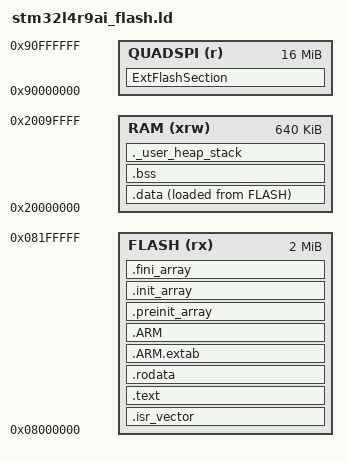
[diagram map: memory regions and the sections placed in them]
/*
******************************************************************************
File:     stm32l4r9ai_flash.ld
Info:     Generated by Atollic TrueSTUDIO(R) 9.2.0   2018-12-17

Abstract: Linker script for STM32L4R9AI device
          Set heap size, stack size, stack location, memory areas and
          sections according to application requirements.

The MIT License (MIT)
Copyright (c) 2018 STMicroelectronics

Permission is hereby granted, free of charge, to any person obtaining a copy
of this software and associated documentation files (the "Software"), to deal
in the Software without restriction, including without limitation the rights
to use, copy, modify, merge, publish, distribute, sublicense, and/or sell
copies of the Software, and to permit persons to whom the Software is
furnished to do so, subject to the following conditions:

The above copyright notice and this permission notice shall be included in all
copies or substantial portions of the Software.

THE SOFTWARE IS PROVIDED "AS IS", WITHOUT WARRANTY OF ANY KIND, EXPRESS OR
IMPLIED, INCLUDING BUT NOT LIMITED TO THE WARRANTIES OF MERCHANTABILITY,
FITNESS FOR A PARTICULAR PURPOSE AND NONINFRINGEMENT. IN NO EVENT SHALL THE
AUTHORS OR COPYRIGHT HOLDERS BE LIABLE FOR ANY CLAIM, DAMAGES OR OTHER
LIABILITY, WHETHER IN AN ACTION OF CONTRACT, TORT OR OTHERWISE, ARISING FROM,
OUT OF OR IN CONNECTION WITH THE SOFTWARE OR THE USE OR OTHER DEALINGS IN THE
SOFTWARE.

******************************************************************************
*/

/* Entry Point */
ENTRY(Reset_Handler)

/* Highest address of the user mode stack */
_estack = 0x200A0000;    /* end of 640K RAM */

/* Generate a link error if heap and stack don't fit into RAM */
_Min_Heap_Size = 0;      /* required amount of heap  */
_Min_Stack_Size = 0x400; /* required amount of stack */

/* Specify the memory areas: 1 SRAM bank */
MEMORY
{
	RAM (xrw)      : ORIGIN = 0x20000000, LENGTH = 640K
	FLASH (rx)     : ORIGIN = 0x8000000,  LENGTH = 2048K
	QUADSPI (r)    : ORIGIN = 0x90000000, LENGTH = 16M
}

/* Define output sections */
SECTIONS
{
  /* The startup code goes first into FLASH */
  .isr_vector :
  {
    . = ALIGN(8);
    KEEP(*(.isr_vector)) /* Startup code */
    . = ALIGN(8);
  } >FLASH

  /* The program code and other data goes into FLASH */
  .text :
  {
    . = ALIGN(8);
    *(.text)           /* .text sections (code) */
    *(.text*)          /* .text* sections (code) */
    *(.glue_7)         /* glue arm to thumb code */
    *(.glue_7t)        /* glue thumb to arm code */
    *(.eh_frame)

    KEEP (*(.init))
    KEEP (*(.fini))

    . = ALIGN(8);
    _etext = .;        /* define a global symbols at end of code */
  } >FLASH

  /* Constant data goes into FLASH */
  .rodata :
  {
    . = ALIGN(8);
    *(.rodata)         /* .rodata sections (constants, strings, etc.) */
    *(.rodata*)        /* .rodata* sections (constants, strings, etc.) */
    . = ALIGN(8);
  } >FLASH

  .ARM.extab   : 
  { 
  . = ALIGN(8);
  *(.ARM.extab* .gnu.linkonce.armextab.*)
  . = ALIGN(8);
  } >FLASH
  .ARM : {
	. = ALIGN(8);
    __exidx_start = .;
    *(.ARM.exidx*)
    __exidx_end = .;
	. = ALIGN(8);
  } >FLASH

  .preinit_array     :
  {
	. = ALIGN(8);
    PROVIDE_HIDDEN (__preinit_array_start = .);
    KEEP (*(.preinit_array*))
    PROVIDE_HIDDEN (__preinit_array_end = .);
	. = ALIGN(8);
  } >FLASH
  .init_array :
  {
	. = ALIGN(8);
    PROVIDE_HIDDEN (__init_array_start = .);
    KEEP (*(SORT(.init_array.*)))
    KEEP (*(.init_array*))
    PROVIDE_HIDDEN (__init_array_end = .);
	. = ALIGN(8);
  } >FLASH
  .fini_array :
  {
	. = ALIGN(8);
    PROVIDE_HIDDEN (__fini_array_start = .);
    KEEP (*(SORT(.fini_array.*)))
    KEEP (*(.fini_array*))
    PROVIDE_HIDDEN (__fini_array_end = .);
	. = ALIGN(8);
  } >FLASH

  /* used by the startup to initialize data */
  _sidata = LOADADDR(.data);

  /* Initialized data sections goes into RAM, load LMA copy after code */
  .data :
  {
    . = ALIGN(8);
    _sdata = .;        /* create a global symbol at data start */
    *(.data)           /* .data sections */
    *(.data*)          /* .data* sections */

    . = ALIGN(8);
    _edata = .;        /* define a global symbol at data end */
  } >RAM AT> FLASH


  /* Uninitialized data section */
  . = ALIGN(4);
  .bss :
  {
    /* This is used by the startup in order to initialize the .bss secion */
    _sbss = .;         /* define a global symbol at bss start */
    __bss_start__ = _sbss;
    *(.bss)
    *(.bss*)
    *(COMMON)

    . = ALIGN(4);
    _ebss = .;         /* define a global symbol at bss end */
    __bss_end__ = _ebss;
  } >RAM

  /* User_heap_stack section, used to check that there is enough RAM left */
  ._user_heap_stack :
  {
    . = ALIGN(8);
    PROVIDE ( end = . );
    PROVIDE ( _end = . );
    . = . + _Min_Heap_Size;
    . = . + _Min_Stack_Size;
    . = ALIGN(8);
  } >RAM


  /* Remove information from the standard libraries */
  /DISCARD/ :
  {
    libc.a ( * )
    libm.a ( * )
    libgcc.a ( * )
  }

  .ARM.attributes 0 : { *(.ARM.attributes) }

  ExtFlashSection :
	{
		*(ExtFlashSection ExtFlashSection.*)
		*(.gnu.linkonce.r.*)
        . = ALIGN(0x4);
	} >QUADSPI
}
